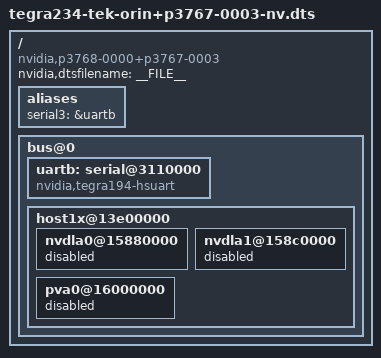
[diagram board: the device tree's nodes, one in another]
// SPDX-License-Identifier: GPL-2.0-only
// SPDX-FileCopyrightText: Copyright (c) 2023-2024, NVIDIA CORPORATION & AFFILIATES.  All rights reserved.

/dts-v1/;

#include "tegra234-tek-orin+p3767-0005.dts"
#include "tegra234-p3768-0000+p3767-xxxx-nv-common.dtsi"

/ {
	compatible = "nvidia,p3768-0000+p3767-0003", "nvidia,p3767-0003", "nvidia,tegra234";
	nvidia,dtsfilename = __FILE__;

	aliases {
		serial3 = &uartb;
	};

	bus@0 {
		uartb: serial@3110000 {
			compatible = "nvidia,tegra194-hsuart";
			reset-names = "serial";
			status = "okay";
		};

		host1x@13e00000 {
			nvdla0@15880000 {
				status = "disabled";
			};

			nvdla1@158c0000 {
				status = "disabled";
			};

			pva0@16000000 {
				status = "disabled";
			};
		};
	};
};
